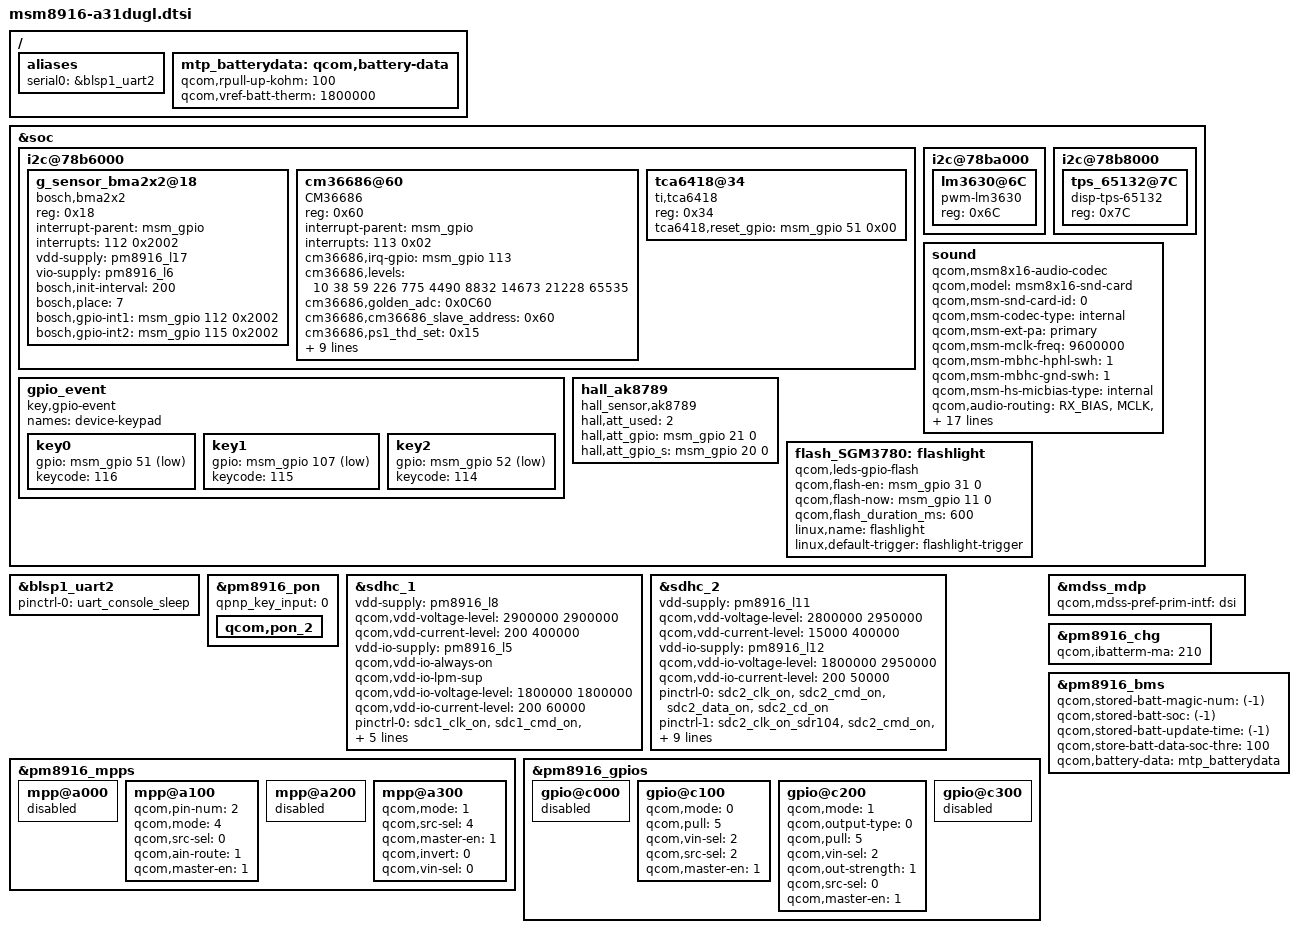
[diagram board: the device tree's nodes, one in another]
/* Copyright (c) 2014, The Linux Foundation. All rights reserved.
 *
 * This program is free software; you can redistribute it and/or modify
 * it under the terms of the GNU General Public License version 2 and
 * only version 2 as published by the Free Software Foundation.
 *
 * This program is distributed in the hope that it will be useful,
 * but WITHOUT ANY WARRANTY; without even the implied warranty of
 * MERCHANTABILITY or FITNESS FOR A PARTICULAR PURPOSE.  See the
 * GNU General Public License for more details.
 */

#include "msm8916.dtsi"
#include "msm8916-pinctrl-a31.dtsi"
#include "msm8916-camera-sensor-a31.dtsi"
#include "dsi-panel-a11.dtsi"
#include "msm8916-touch-a31-config.dtsi"
#include "msm8916-ncp6924.dtsi"
#include "dsi-panel-a31.dtsi"

/ {
	aliases {
		serial0 = &blsp1_uart2;
	};
};

&soc {
	i2c@78b6000 {
		g_sensor_bma2x2@18 {
			compatible = "bosch,bma2x2";
			reg = <0x18>;
			pinctrl-names = "default";
			//pinctrl-0 = <&bma2x2_int1_default &bma2x2_int2_default>;
			interrupt-parent = <&msm_gpio>;
			interrupts = <112 0x2002>;
			vdd-supply = <&pm8916_l17>;
			vio-supply = <&pm8916_l6>;
			bosch,init-interval = <200>;
			bosch,place = <7>;
			bosch,gpio-int1 = <&msm_gpio 112 0x2002>;
			bosch,gpio-int2 = <&msm_gpio 115 0x2002>;
		};

                cm36686@60 {
                        compatible = "CM36686";
                        reg = <0x60>;
                        interrupt-parent = <&msm_gpio>;
                        interrupts = <113 0x02>;
                        interrupt-names = "cm36686";
                        cm36686,irq-gpio = <&msm_gpio 113 0x00>;
                        cm36686,levels = <10 38 59 226 775 4490 8832 14673 21228 65535>;
                        cm36686,golden_adc = <0x0C60>;
                        cm36686,cm36686_slave_address = <0x60>;
                        cm36686,ps1_thd_set = <0x15>;
                        cm36686,ps1_thd_no_cal = <0x5f>;
                        cm36686,dynamical_threshold = <1>;
                        cm36686,dark_level = <3>;
                        cm36686,ps_duty = <0>;
                        cm36686,ps_pers = <1>;
                        cm36686,ps_it = <7>;
                        cm36686,ps_hd = <0>;
                        cm36686,ps_led_current = <2>;
			SR_2v85-supply = <&pm8916_l17>;
                };

		tca6418@34 {
			compatible = "ti,tca6418";
			reg = <0x34>;
			tca6418,reset_gpio = <&msm_gpio 51 0x00>;
		};
	};

	i2c@78ba000 { /* BLSP1 QUP6 */
		lm3630@6C {
			compatible = "pwm-lm3630";
			reg = <0x6C>;
		};
	};

	i2c@78b8000 {
		tps_65132@7C {
			compatible = "disp-tps-65132";
			reg = <0x7C>;
		};
	};

	sound {
		compatible = "qcom,msm8x16-audio-codec";
		qcom,model = "msm8x16-snd-card";
		qcom,msm-snd-card-id = <0>;
		qcom,msm-codec-type = "internal";
		qcom,msm-ext-pa = "primary";
		qcom,msm-mclk-freq = <9600000>;
		qcom,msm-mbhc-hphl-swh = <1>;
		qcom,msm-mbhc-gnd-swh = <1>;
		qcom,msm-hs-micbias-type = "internal";
		qcom,audio-routing =
			"RX_BIAS", "MCLK",
			"SPK_RX_BIAS", "MCLK",
			"INT_LDO_H", "MCLK",
			"MIC BIAS Internal1", "Handset Mic",
			"MIC BIAS Internal2", "Headset Mic",
			"MIC BIAS Internal3", "Secondary Mic",
			"AMIC1", "MIC BIAS Internal1",
			"AMIC2", "MIC BIAS Internal2",
			"AMIC3", "MIC BIAS Internal3";
		pinctrl-names = "cdc_lines_act",
				"cdc_lines_sus",
				"cdc_lines_sec_ext_act",
				"cdc_lines_sec_ext_sus",
				"cross_conn_det_act",
				"cross_conn_det_sus";
		pinctrl-0 = <&cdc_pdm_lines_act>;
		pinctrl-1 = <&cdc_pdm_lines_sus>;
		pinctrl-2 = <&cdc_pdm_lines_act &cdc_ext_pa_act
						&cdc_ext_pa_ws_act>;
		pinctrl-3 = <&cdc_pdm_lines_sus &cdc_ext_pa_sus
						&cdc_ext_pa_ws_sus>;
		pinctrl-4 = <&cross_conn_det_act>;
		pinctrl-5 = <&cross_conn_det_sus>;
//		qcom,cdc-us-euro-gpios = <&msm_gpio 120 0>;
		htc,aud-digital-mic-en = <0>;
		htc,aud-24b-en = <0>;
	};
};

&blsp1_uart2 {
	status = "ok";
	pinctrl-names = "default";
	pinctrl-0 = <&uart_console_sleep>;
};

&pm8916_pon {
	qpnp_key_input = <0>;
	qcom,pon_2 {
		//linux,code = <114>;
	};
};

&soc {
	gpio_event {
		compatible = "key,gpio-event";
		names = "device-keypad";
		//clr_gpio = <&msm_gpio 2 0>;
		//cmcc_disable_reset = <1>;

		key0 {
			gpio    = <&msm_gpio 51 3>;
			keycode = <116>;	//pwr
			//pull = <1>;		//0=pull up, 1=no pull
		};
		key1 {
			gpio    = <&msm_gpio 107 3>;
			keycode = <115>;	//vUP
		};
		key2 {
			gpio    = <&msm_gpio 52 3>;
			keycode = <114>;	//vDN
		};
	};

//	keyreset {
//		compatible = "keyreset_driver";
//		keyreset,driver_state = "enable";
//	};

	hall_ak8789 {
		compatible = "hall_sensor,ak8789";
		hall,att_used = <2>;
		hall,att_gpio = <&msm_gpio 21 0>;
		hall,att_gpio_s = <&msm_gpio 20 0>;
	};

	flash_SGM3780:flashlight {
                compatible = "qcom,leds-gpio-flash";
                status = "okay";
                qcom,flash-en = <&msm_gpio 31 0>;
                qcom,flash-now = <&msm_gpio 11 0>;
		qcom,flash_duration_ms = <600>;
                linux,name = "flashlight";
		linux,default-trigger = "flashlight-trigger";
        };
};

&sdhc_1 {
	vdd-supply = <&pm8916_l8>;
	qcom,vdd-voltage-level = <2900000 2900000>;
	qcom,vdd-current-level = <200 400000>;

	vdd-io-supply = <&pm8916_l5>;
	qcom,vdd-io-always-on;
	qcom,vdd-io-lpm-sup;
	qcom,vdd-io-voltage-level = <1800000 1800000>;
	qcom,vdd-io-current-level = <200 60000>;

	pinctrl-names = "active", "sleep";
	pinctrl-0 = <&sdc1_clk_on &sdc1_cmd_on &sdc1_data_on>;
	pinctrl-1 = <&sdc1_clk_off &sdc1_cmd_off &sdc1_data_off>;
	htc,slot-type = <0>;
	qcom,nonremovable;

	status = "ok";
};

&sdhc_2 {
	vdd-supply = <&pm8916_l11>;
	qcom,vdd-voltage-level = <2800000 2950000>;
	qcom,vdd-current-level = <15000 400000>;

	vdd-io-supply = <&pm8916_l12>;
	qcom,vdd-io-voltage-level = <1800000 2950000>;
	qcom,vdd-io-current-level = <200 50000>;

	pinctrl-names = "active", "active_sdr104", "sleep";
	pinctrl-0 = <&sdc2_clk_on &sdc2_cmd_on &sdc2_data_on &sdc2_cd_on>;
	pinctrl-1 = <&sdc2_clk_on_sdr104 &sdc2_cmd_on &sdc2_data_on &sdc2_cd_on>;
	pinctrl-2 = <&sdc2_clk_off &sdc2_cmd_off &sdc2_data_off &sdc2_cd_off>;

	#address-cells = <0>;
	interrupt-parent = <&sdhc_2>;
	interrupts = <0 1 2>;
	#interrupt-cells = <1>;
	interrupt-map-mask = <0xffffffff>;
	interrupt-map = <0 &intc 0 125 0
			1 &intc 0 221 0
			2 &msm_gpio 38 0>;
	interrupt-names = "hc_irq", "pwr_irq", "status_irq";
	htc,slot-type = <1>;

	status = "ok";
};

&pm8916_mpps {
	mpp@a000 { /* MPP 1 */
		/* VDD_PX */
		status = "disabled";
	};

	mpp@a100 { /* MPP 2 */
		/* HR LED */
		qcom,pin-num = <2>;
                qcom,mode      = <4>;   //QPNP_PIN_MODE_AIN
                qcom,src-sel   = <0>;   //QPNP_PIN_SEL_FUNC_CONSTANT
                qcom,ain-route = <1>;   //QPNP_PIN_AIN_AMUX_CH8
                qcom,master-en = <1>;   //ENABLE FEATURE
	};

	mpp@a200 { /* MPP 3 */
		/* VREF DAC */
		status = "disabled";
	};

	mpp@a300 { /* MPP 4 */
		/* Backlight PWM */
		qcom,mode      = <1>;  /* Digital output */
		qcom,src-sel   = <4>;  /* DTEST1 */
		qcom,master-en = <1>;  /* Enable MPP */
		qcom,invert = <0>;     /* Disable invert */
		qcom,vin-sel = <0>;    /* VPH_PWR */
	};
};

&pm8916_gpios {
	gpio@c000 { /* GPIO 1 */
		/* Battery UICC Alarm */
		status = "disabled";
	};

	gpio@c100 { /* GPIO 2 */
		/* NFC_CLK_REQ */
		qcom,mode = <0>; /* QPNP_PIN_MODE_DIG_IN */
		qcom,pull = <5>; /* QPNP_PIN_PULL_NO */
		qcom,vin-sel = <2>; /* QPNP_PIN_VIN2 */
		qcom,src-sel = <2>; /* QPNP_PIN_SEL_FUNC_1 */
		qcom,master-en = <1>;
	};

	gpio@c200 { /* GPIO 3 */
		qcom,mode = <1>; /* QPNP_PIN_MODE_DIG_OUT */
		qcom,output-type = <0>; /* QPNP_PIN_OUT_BUF_CMOS */
		qcom,pull = <5>; /* QPNP_PIN_PULL_NO */
		qcom,vin-sel = <2>; /* QPNP_PIN_VIN2 */
		qcom,out-strength = <1>; /* QPNP_PIN_OUT_STRENGTH_LOW */
		qcom,src-sel = <0>; /* QPNP_PIN_SEL_FUNC_CONSTANT */
		qcom,master-en = <1>;
	};

	gpio@c300 { /* GPIO 4 */
		/* External regulator control for APC */
		status = "disabled";
	};
};

&mdss_mdp {
	qcom,mdss-pref-prim-intf = "dsi";
};

&pm8916_chg {
	qcom,ibatterm-ma = <210>;
	status = "ok";
};

/ {
	mtp_batterydata: qcom,battery-data {
		qcom,rpull-up-kohm = <100>;
		qcom,vref-batt-therm = <1800000>;

		#include "batterydata-a31-id2.dtsi"
	};
};

&pm8916_bms {
	qcom,stored-batt-magic-num= <(-1)>;
	qcom,stored-batt-soc= <(-1)>;
	qcom,stored-batt-update-time= <(-1)>;
	qcom,store-batt-data-soc-thre = <100>;
	status = "ok";
	qcom,battery-data = <&mtp_batterydata>;
};
